# HDSC_HC32L186 register map
Vendor: HDSC Co.Ltd; Series: ARMCM0P; File version: 1.2
CPU: CM0 r0p0, little endian, no MPU, no FPU, 3 interrupt priority bits
Registers are 32-bit, read-write, reset 0x0 unless marked. A register's access mark holds for its fields unless they carry their own. Offsets are from the block's base; [hi:lo] are bit positions; {n}, {i} and the like mark numbered series.

## I2C0 — desc I2C
Base 0x40000400
Same registers: I2C1 0x40004400
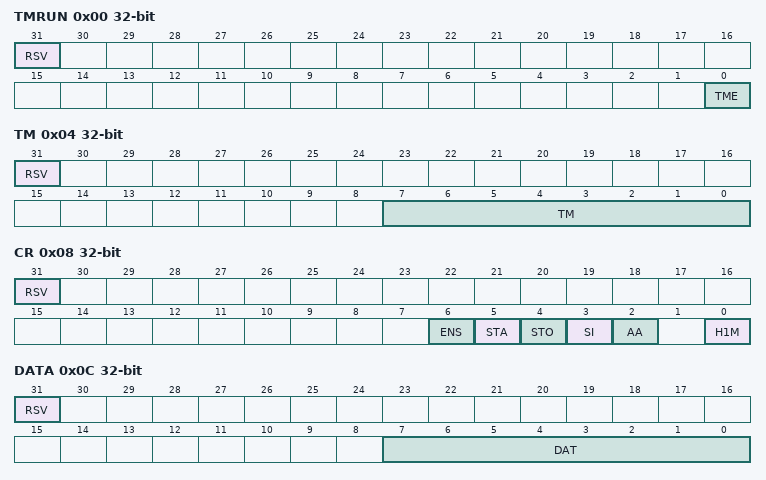
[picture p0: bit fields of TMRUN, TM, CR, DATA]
0x00 TMRUN (reset mask 0x1)
  [31] RSV, [0] TME
0x04 TM (reset mask 0xFF)
  [31] RSV, [7:0] TM
0x08 CR (reset mask 0x7D)
  [31] RSV, [6] ENS, [5] STA, [4] STO, [3] SI, [2] AA, [0] H1M
0x0C DATA (reset mask 0xFF)
  [31] RSV, [7:0] DAT
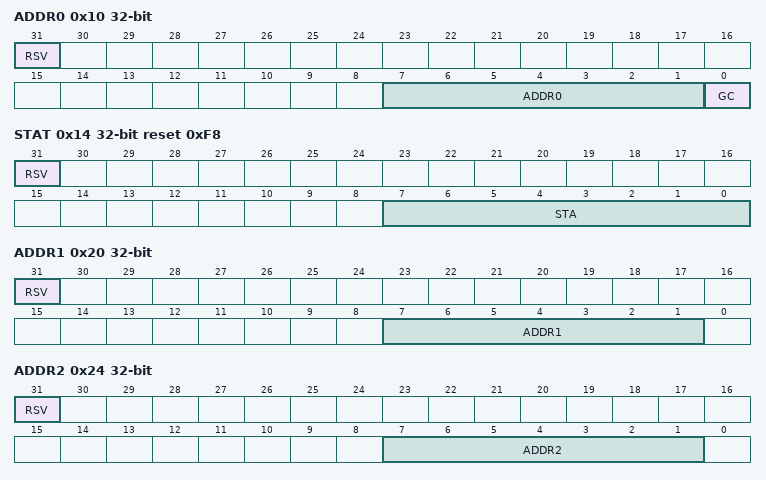
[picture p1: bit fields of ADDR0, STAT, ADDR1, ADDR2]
0x10 ADDR0 (reset mask 0xFF)
  [31] RSV, [7:1] ADDR0, [0] GC
0x14 STAT ro reset 0xF8 (reset mask 0xFF)
  [31] RSV rw, [7:0] STA
0x20 ADDR1 (reset mask 0xFE)
  [31] RSV, [7:1] ADDR1
0x24 ADDR2 (reset mask 0xFE)
  [31] RSV, [7:1] ADDR2
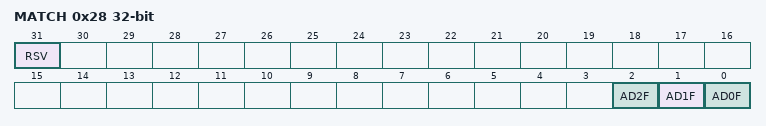
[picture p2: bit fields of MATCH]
0x28 MATCH ro (reset mask 0x7)
  [31] RSV, [2] AD2F, [1] AD1F, [0] AD0F

## LCD
Base 0x40005C00
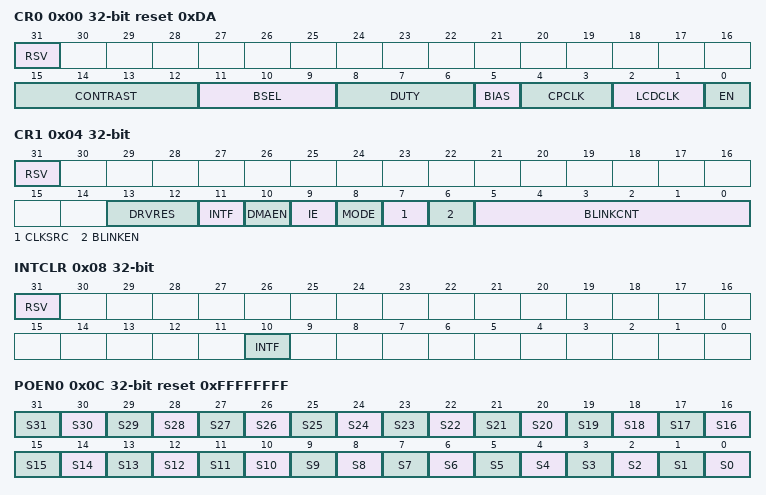
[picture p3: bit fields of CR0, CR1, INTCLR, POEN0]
0x00 CR0 reset 0xDA (reset mask 0xFFFF)
  [31] RSV, [15:12] CONTRAST, [11:9] BSEL, [8:6] DUTY, [5] BIAS, [4:3] CPCLK, [2:1] LCDCLK, [0] EN
0x04 CR1 (reset mask 0x3FFF)
  [31] RSV ro, [13:12] DRVRES, [11] INTF ro, [10] DMAEN, [9] IE, [8] MODE, [7] CLKSRC, [6] BLINKEN, [5:0] BLINKCNT
0x08 INTCLR wo (reset mask 0x400)
  [31] RSV rw, [10] INTF
0x0C POEN0 reset 0xFFFFFFFF
  [n] S{n} (n=0..31)
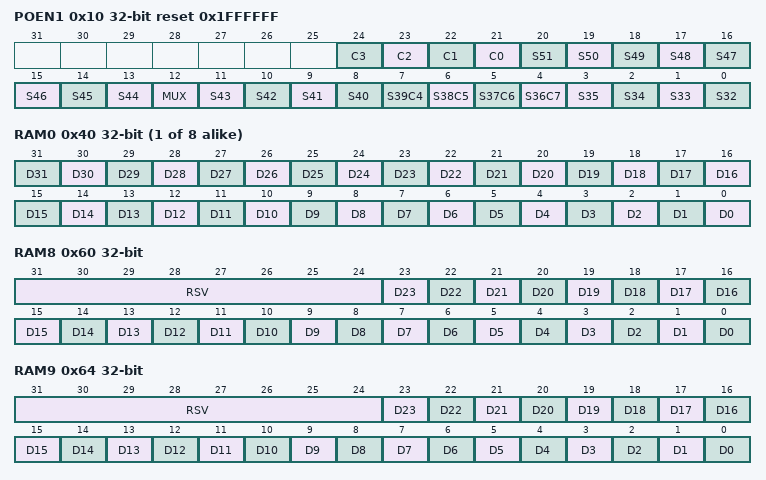
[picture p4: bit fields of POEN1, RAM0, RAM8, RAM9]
0x10 POEN1 reset 0x1FFFFFF
  [n+21] C{n} (n=0..3), [n-31] S{n} (n=44..51), [12] MUX, [n-32] S{n} (n=40..43), [7] S39C4, [6] S38C5, [5] S37C6, [4] S36C7, [n-32] S{n} (n=32..35)
{0x40+4i} RAM{i} (i=0..7)
  [n] D{n} (n=0..31)
0x60 RAM8 (reset mask 0xFFFFFF)
  [31:24] RSV, [n] D{n} (n=0..23)
0x64 RAM9 (reset mask 0xFFFFFF)
  [31:24] RSV, [n] D{n} (n=0..23)
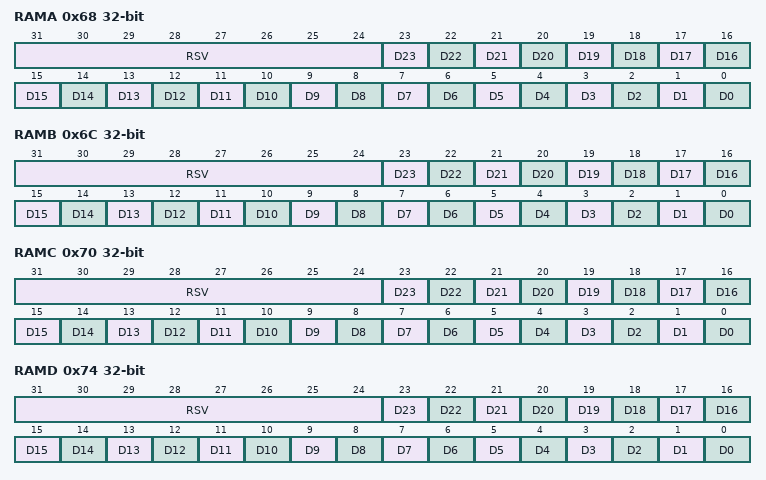
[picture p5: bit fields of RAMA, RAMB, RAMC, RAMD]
0x68 RAMA (reset mask 0xFFFFFF)
  [31:24] RSV, [n] D{n} (n=0..23)
0x6C RAMB (reset mask 0xFFFFFF)
  [31:24] RSV, [n] D{n} (n=0..23)
0x70 RAMC (reset mask 0xFFFFFF)
  [31:24] RSV, [n] D{n} (n=0..23)
0x74 RAMD (reset mask 0xFFFFFF)
  [31:24] RSV, [n] D{n} (n=0..23)
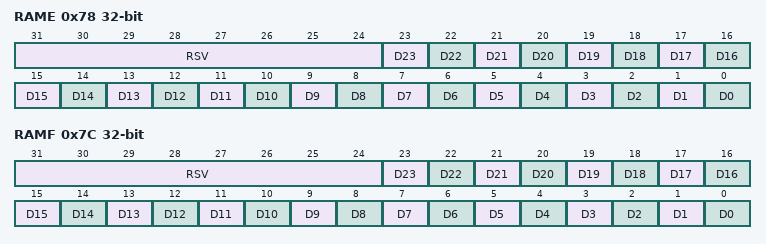
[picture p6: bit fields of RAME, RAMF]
0x78 RAME (reset mask 0xFFFFFF)
  [31:24] RSV, [n] D{n} (n=0..23)
0x7C RAMF (reset mask 0xFFFFFF)
  [31:24] RSV, [n] D{n} (n=0..23)

## LPTIMER0 — desc LPTIMER
Base 0x40000F00
Same registers: LPTIMER1 0x40000F40
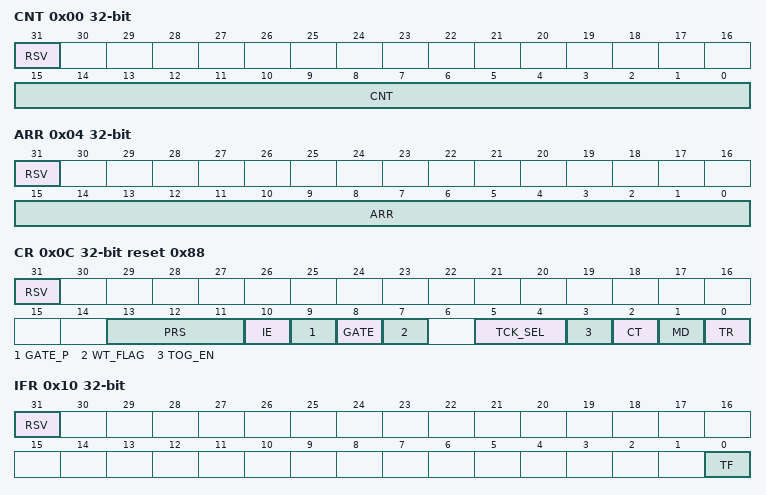
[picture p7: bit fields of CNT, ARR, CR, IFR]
0x00 CNT ro (reset mask 0xFFFF)
  [31] RSV rw, [15:0] CNT
0x04 ARR (reset mask 0xFFFF)
  [31] RSV, [15:0] ARR
0x0C CR reset 0x88 (reset mask 0x3FBF)
  [31] RSV, [13:11] PRS, [10] IE, [9] GATE_P, [8] GATE, [7] WT_FLAG ro, [5:4] TCK_SEL, [3] TOG_EN, [2] CT, [1] MD, [0] TR
0x10 IFR ro (reset mask 0x1)
  [31] RSV rw, [0] TF
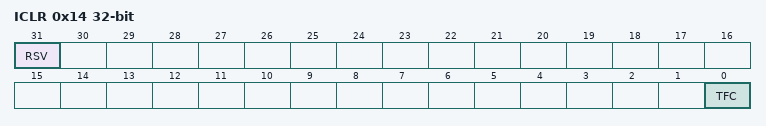
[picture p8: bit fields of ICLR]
0x14 ICLR wo (reset mask 0x1)
  [31] RSV rw, [0] TFC

## LPUART0 — desc LPUART
Base 0x40000200
Same registers: LPUART1 0x40004000
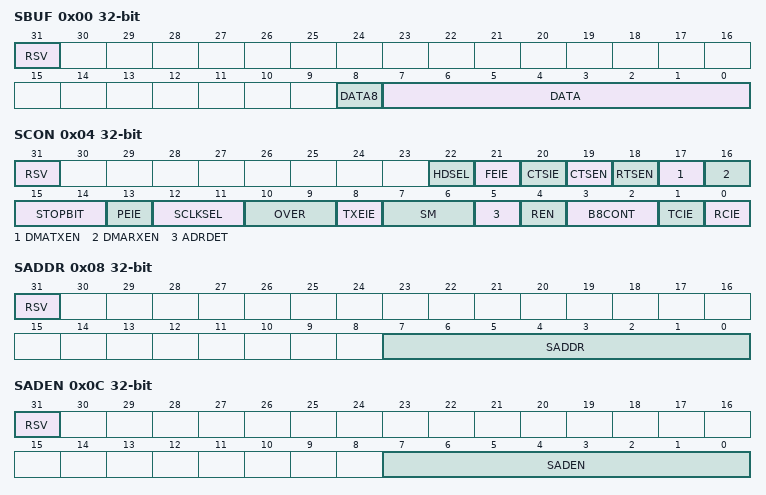
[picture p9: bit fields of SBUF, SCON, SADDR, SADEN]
0x00 SBUF (reset mask 0x1FF)
  [31] RSV, [8] DATA8, [7:0] DATA
0x04 SCON (reset mask 0x7FFFFF)
  [31] RSV, [22] HDSEL, [21] FEIE, [20] CTSIE, [19] CTSEN, [18] RTSEN, [17] DMATXEN, [16] DMARXEN, [15:14] STOPBIT, [13] PEIE, [12:11] SCLKSEL, [10:9] OVER, [8] TXEIE, [7:6] SM, [5] ADRDET, [4] REN, [3:2] B8CONT, [1] TCIE, [0] RCIE
0x08 SADDR (reset mask 0xFF)
  [31] RSV, [7:0] SADDR
0x0C SADEN (reset mask 0xFF)
  [31] RSV, [7:0] SADEN
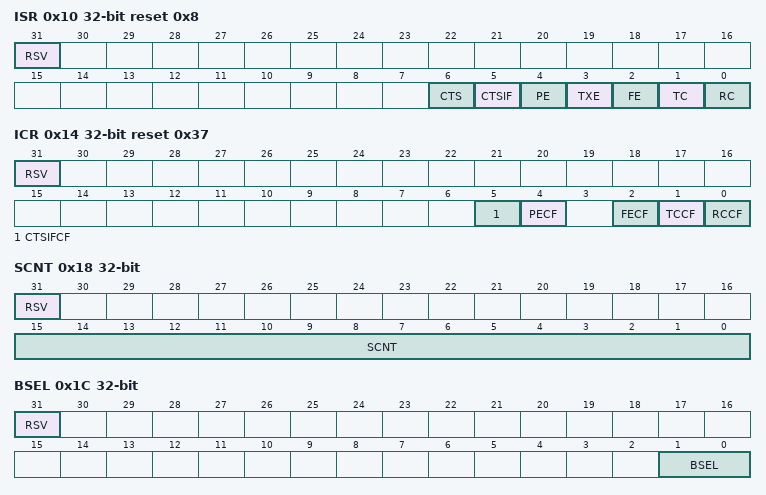
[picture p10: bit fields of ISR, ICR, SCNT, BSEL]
0x10 ISR ro reset 0x8 (reset mask 0x7F)
  [31] RSV rw, [6] CTS, [5] CTSIF, [4] PE, [3] TXE, [2] FE, [1] TC, [0] RC
0x14 ICR wo reset 0x37 (reset mask 0x37)
  [31] RSV rw, [5] CTSIFCF, [4] PECF, [2] FECF, [1] TCCF, [0] RCCF
0x18 SCNT (reset mask 0xFFFF)
  [31] RSV, [15:0] SCNT
0x1C BSEL (reset mask 0x3)
  [31] RSV, [1:0] BSEL
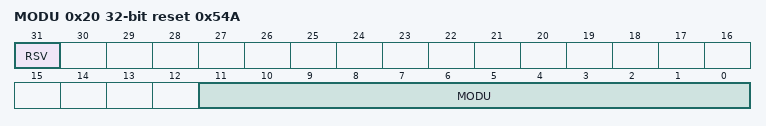
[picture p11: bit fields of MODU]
0x20 MODU reset 0x54A (reset mask 0xFFF)
  [31] RSV, [11:0] MODU

## LVD
Base 0x40002400; alternate view of ADC
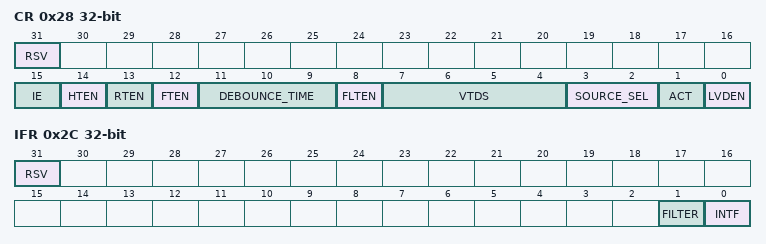
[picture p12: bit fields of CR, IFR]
0x28 CR (reset mask 0xFFFF)
  [31] RSV, [15] IE, [14] HTEN, [13] RTEN, [12] FTEN, [11:9] DEBOUNCE_TIME, [8] FLTEN, [7:4] VTDS, [3:2] SOURCE_SEL, [1] ACT, [0] LVDEN
0x2C IFR (reset mask 0x3)
  [31] RSV, [1] FILTER, [0] INTF

## OPA
Base 0x40002400; alternate view of ADC
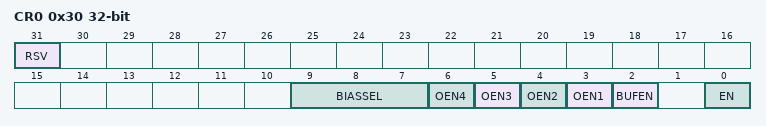
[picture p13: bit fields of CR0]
0x30 CR0 (reset mask 0xFFF)
  [31] RSV, [9:7] BIASSEL, [n+2] OEN{n} (n=1..4), [2] BUFEN, [0] EN
